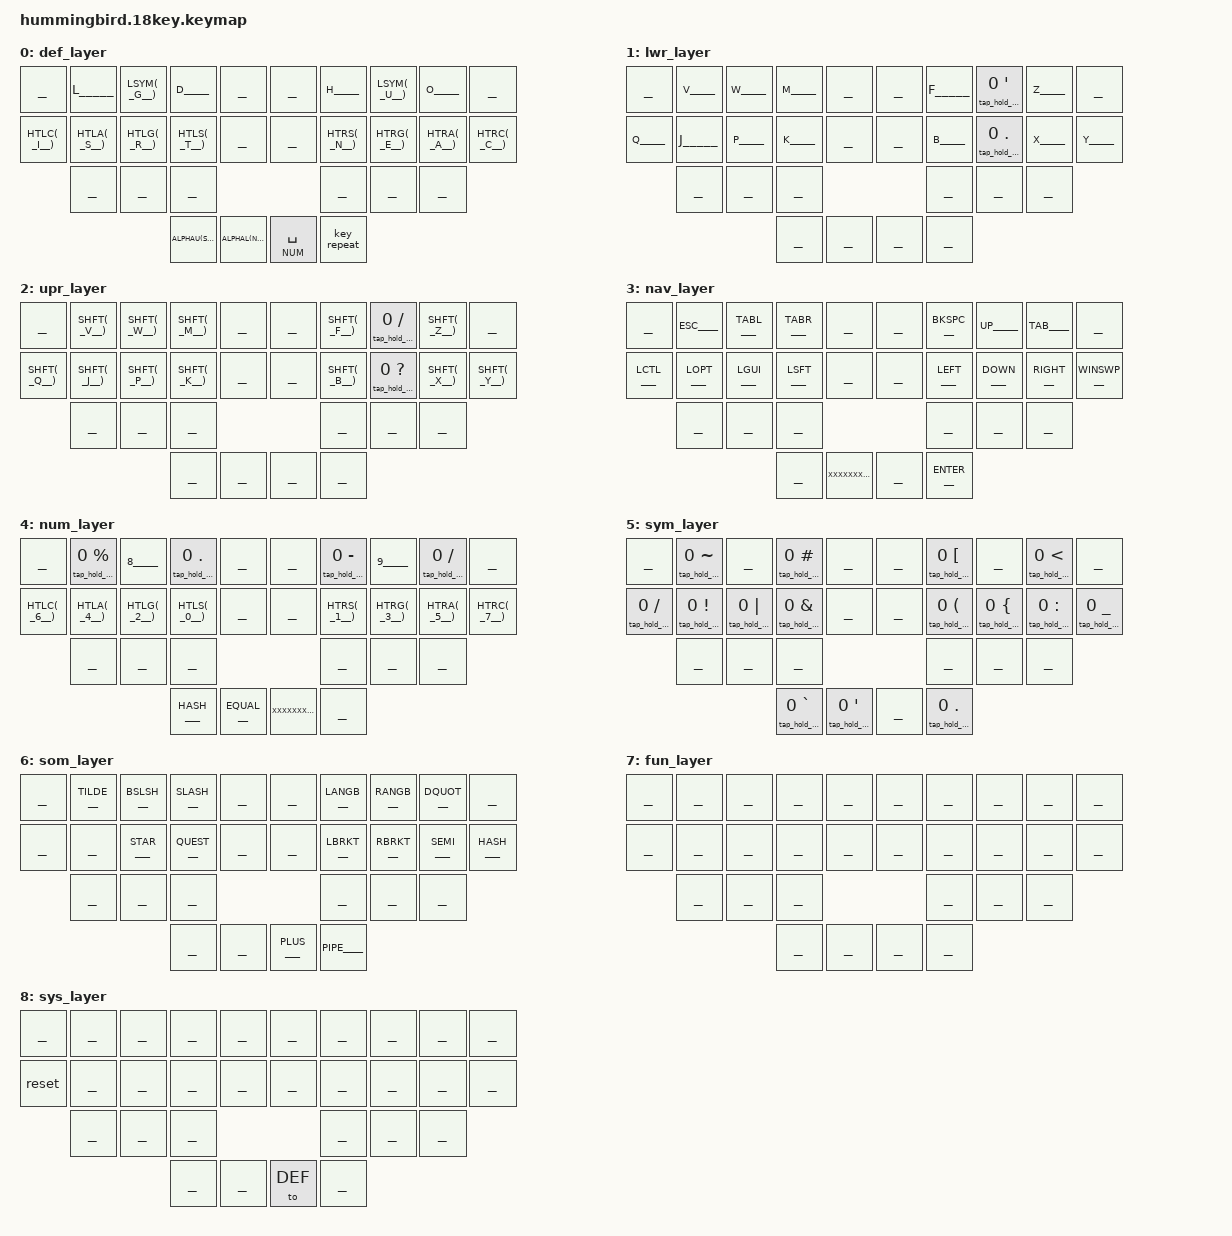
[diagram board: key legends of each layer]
#define HOST_OS 2

#include <behaviors.dtsi>
#include <dt-bindings/zmk/keys.h>
#include <dt-bindings/zmk/bt.h>

#include "./hummingbird.helpers.h"
#include "./nodefree/helpers.h"
#include "./nodefree/keypos_30key.h"
#include "./keycodes.h"

/**
 * ----------------------------------------------
 * DEFAULT ALPHA LAYER
 * ----------------------------------------------
 */ 
ZMK_COMBO(caps_word, &caps_word,  LM1 RM1, DEF, 80)
ZMK_COMBO(esc,       &kp ESC,   LT2 LT1, DEF, 40)

#define LSYM(KEY) HL(SYM, KEY) 


ZMK_LAYER(def_layer,
// ╭─────────────┬─────────────┬─────────────┬─────────────┬─────────────╮   ╭─────────────┬─────────────┬─────────────┬─────────────┬─────────────╮
     ___________   _____L_____   LSYM(__G__)   _____D_____   ___________       ___________   _____H_____   LSYM(__U__)   _____O_____   ___________ 
// ├─────────────┼─────────────┼─────────────┼─────────────┼─────────────┤   ├─────────────┼─────────────┼─────────────┼─────────────┼─────────────┤
     HTLC(__I__)   HTLA(__S__)   HTLG(__R__)   HTLS(__T__)   ___________       ___________   HTRS(__N__)   HTRG(__E__)   HTRA(__A__)   HTRC(__C__) 
// ├─────────────┼─────────────┼─────────────┼─────────────┼─────────────┤   ╰─────────────┼─────────────┼─────────────┼─────────────┼─────────────╯
                   ___________   ___________   ___________                                   ___________   ___________   ___________ 
//               ╰─────────────┼─────────────┼─────────────╯                               ╰─────────────┴─────────────┴─────────────╯
                                               ALPHAU(SYM)   ALPHAL(NAV)       &lt NUM SPC   &key_repeat
//                                           ╰─────────────┴─────────────╯   ╰─────────────┴─────────────╯
)


/**
 * ----------------------------------------------
 * LOWER ALPHA LAYER
 * ----------------------------------------------
 */ 
TAP_HOLD_MACRO(QUOTE, DOUBLE_QUOTES)
#define ___QUOTE___ &tap_hold_QUOTE 0 SINGLE_QUOTE

TAP_HOLD_MACRO(DOTCM, COMMA)
#define ___DOTCM___ &tap_hold_DOTCM 0 DOT

ZMK_UNICODE_SINGLE(da_ae_lwr, N0, N0, E, N6)
ZMK_UNICODE_SINGLE(da_oe_lwr, N0, N0, F, N8)
ZMK_UNICODE_SINGLE(da_aa_lwr, N0, N0, E, N5)

ZMK_COMBO(da_ae_lwr, &da_ae_lwr, RM2 RM1, LWR, 50)
ZMK_COMBO(da_oe_lwr, &da_oe_lwr, RM3 RM2, LWR, 50)
ZMK_COMBO(da_aa_lwr, &da_aa_lwr, RM4 RM3, LWR, 50)

ZMK_LAYER(lwr_layer,
// ╭─────────────┬─────────────┬─────────────┬─────────────┬─────────────╮   ╭─────────────┬─────────────┬─────────────┬─────────────┬─────────────╮
     ___________   _____V_____   _____W_____   _____M_____   ___________       ___________   _____F_____   ___QUOTE___   _____Z_____   ___________ 
// ├─────────────┼─────────────┼─────────────┼─────────────┼─────────────┤   ├─────────────┼─────────────┼─────────────┼─────────────┼─────────────┤
     _____Q_____   _____J_____   _____P_____   _____K_____   ___________       ___________   _____B_____   ___DOTCM___   _____X_____   _____Y_____ 
// ├─────────────┼─────────────┼─────────────┼─────────────┼─────────────┤   ╰─────────────┼─────────────┼─────────────┼─────────────┼─────────────╯
                   ___________   ___________   ___________                                   ___________   ___________   ___________ 
//               ╰─────────────┼─────────────┼─────────────╯                               ╰─────────────┴─────────────┴─────────────╯
                                               ___________   ___________       ___________   ___________
//                                           ╰─────────────┴─────────────╯   ╰─────────────┴─────────────╯
)


/**
 * ----------------------------------------------
 * UPPER ALPHA LAYER
 * ----------------------------------------------
 */ 
#define SHFT(KEY) &kp LS(KEY)

TAP_HOLD_MACRO(QUEX, EXCLAMATION)
#define ___QUEX____ &tap_hold_QUEX 0 QUESTION

TAP_HOLD_MACRO(SLBSL, BACKSLASH)
#define ___SLBSL___ &tap_hold_SLBSL 0 SLASH

ZMK_UNICODE_SINGLE(da_ae_upr, N0, N0, C, N6)
ZMK_UNICODE_SINGLE(da_oe_upr, N0, N0, D, N8)
ZMK_UNICODE_SINGLE(da_aa_upr, N0, N0, C, N5)

ZMK_COMBO(da_ae_upr, &da_ae_upr, RM2 RM1, UPR, 50)
ZMK_COMBO(da_oe_upr, &da_oe_upr, RM3 RM2, UPR, 50)
ZMK_COMBO(da_aa_upr, &da_aa_upr, RM4 RM3, UPR, 50)

ZMK_LAYER(upr_layer,
// ╭─────────────┬─────────────┬─────────────┬─────────────┬─────────────╮   ╭─────────────┬─────────────┬─────────────┬─────────────┬─────────────╮
     ___________   SHFT(__V__)   SHFT(__W__)   SHFT(__M__)   ___________       ___________   SHFT(__F__)   ___SLBSL___   SHFT(__Z__)   ___________ 
// ├─────────────┼─────────────┼─────────────┼─────────────┼─────────────┤   ├─────────────┼─────────────┼─────────────┼─────────────┼─────────────┤
     SHFT(__Q__)   SHFT(__J__)   SHFT(__P__)   SHFT(__K__)   ___________       ___________   SHFT(__B__)   ___QUEX____   SHFT(__X__)   SHFT(__Y__) 
// ├─────────────┼─────────────┼─────────────┼─────────────┼─────────────┤   ╰─────────────┼─────────────┼─────────────┼─────────────┼─────────────╯
                   ___________   ___________   ___________                                   ___________   ___________   ___________ 
//               ╰─────────────┼─────────────┼─────────────╯                               ╰─────────────┴─────────────┴─────────────╯
                                               ___________   ___________       ___________   ___________
//                                           ╰─────────────┴─────────────╯   ╰─────────────┴─────────────╯
)


/**
 * ----------------------------------------------
 * NAV LAYER
 * ----------------------------------------------
 */ 
ZMK_COMBO(copy,      &kp LG(C), LM3 LM2, NAV, 20)
ZMK_COMBO(cut,       &kp LG(X), LM3 LM1, NAV, 20)
ZMK_COMBO(paste,     &kp LG(V), LM2 LM1, NAV, 20)
ZMK_COMBO(tab,       &kp TAB,   RM2 RM1, NAV, 40)

ZMK_LAYER(nav_layer,
// ╭─────────────┬─────────────┬─────────────┬─────────────┬─────────────╮   ╭─────────────┬─────────────┬─────────────┬─────────────┬─────────────╮
     ___________   ____ESC____   ___TABL____   ___TABR____   ___________       ___________   ___BKSPC___   ____UP_____   ____TAB____   ___________ 
// ├─────────────┼─────────────┼─────────────┼─────────────┼─────────────┤   ├─────────────┼─────────────┼─────────────┼─────────────┼─────────────┤
     ___LCTL____   ___LOPT____   ___LGUI____   ___LSFT____   ___________       ___________   ___LEFT____   ___DOWN____   ___RIGHT___   __WINSWP___ 
// ├─────────────┼─────────────┼─────────────┼─────────────┼─────────────┤   ╰─────────────┼─────────────┼─────────────┼─────────────┼─────────────╯
                   ___________   ___________   ___________                                   ___________   ___________   ___________ 
//               ╰─────────────┼─────────────┼─────────────╯                               ╰─────────────┴─────────────┴─────────────╯
                                               ___________   XXXXXXXXXXX       ___________   ___ENTER___
//                                           ╰─────────────┴─────────────╯   ╰─────────────┴─────────────╯
)

/**
 * ----------------------------------------------
 * NUM LAYER
 * ----------------------------------------------
 */ 
TAP_HOLD_MACRO(MINPLUS, PLUS)
#define __MINPLUS__ &tap_hold_MINPLUS 0 MINUS 

TAP_HOLD_MACRO(SLASTAR, STAR)
#define __SLASTAR__ &tap_hold_SLASTAR 0 SLASH 

TAP_HOLD_MACRO(PERCAR, CARET)
#define __PERCAR___ &tap_hold_PERCAR 0 PERCENT 

ZMK_LAYER(num_layer,
// ╭─────────────┬─────────────┬─────────────┬─────────────┬─────────────╮   ╭─────────────┬─────────────┬─────────────┬─────────────┬─────────────╮
     ___________   __PERCAR___   _____8_____   ___DOTCM___   ___________       ___________   __MINPLUS__   _____9_____   __SLASTAR__   ___________ 
// ├─────────────┼─────────────┼─────────────┼─────────────┼─────────────┤   ├─────────────┼─────────────┼─────────────┼─────────────┼─────────────┤
     HTLC(__6__)   HTLA(__4__)   HTLG(__2__)   HTLS(__0__)   ___________       ___________   HTRS(__1__)   HTRG(__3__)   HTRA(__5__)   HTRC(__7__)
// ├─────────────┼─────────────┼─────────────┼─────────────┼─────────────┤   ╰─────────────┼─────────────┼─────────────┼─────────────┼─────────────╯
                   ___________   ___________   ___________                                   ___________   ___________   ___________ 
//               ╰─────────────┼─────────────┼─────────────╯                               ╰─────────────┴─────────────┴─────────────╯
                                               ___HASH____   ___EQUAL___       XXXXXXXXXXX   ___________
//                                           ╰─────────────┴─────────────╯   ╰─────────────┴─────────────╯
)


/**
 * ----------------------------------------------
 * SYM LAYER
 * ----------------------------------------------
 */ 
TAP_HOLD_MACRO(PARN, RIGHT_PARENTHESIS)
#define ___PARN____ &tap_hold_PARN 0 LEFT_PARENTHESIS

TAP_HOLD_MACRO(BRAC, RIGHT_BRACE)
#define ___BRAC____ &tap_hold_BRAC 0 LEFT_BRACE

TAP_HOLD_MACRO(BRKT, RIGHT_BRACKET)
#define ___BRKT____ &tap_hold_BRKT 0 LEFT_BRACKET

TAP_HOLD_MACRO(ANGB, GREATER_THAN)
#define ___ANGB____ &tap_hold_ANGB 0 LESS_THAN

TAP_HOLD_MACRO(TILCAR_, CARET)
#define __TILCAR___ &tap_hold_TILCAR_ 0 TILDE

TAP_HOLD_MACRO(HASHAT, AT_SIGN)
#define __HASHAT___ &tap_hold_HASHAT 0 HASH

TAP_HOLD_MACRO(BANGSTR, STAR)
#define __BANGSTR__ &tap_hold_BANGSTR 0 EXCLAMATION

TAP_HOLD_MACRO(PIPER, PERCENT)
#define ___PIPER___ &tap_hold_PIPER 0 PIPE

TAP_HOLD_MACRO(AMPEQ, EQUAL)
#define ___AMPEQ___ &tap_hold_AMPEQ 0 AMPERSAND

TAP_HOLD_MACRO(GRVDLR, DOLLAR)
#define __GRVDLR___ &tap_hold_GRVDLR 0 GRAVE

TAP_HOLD_MACRO(DOTHUH, QUESTION)
#define __DOTHUH___ &tap_hold_DOTHUH 0 DOT

TAP_HOLD_MACRO(COLSEMI, SEMICOLON)
#define __COLSEMI__ &tap_hold_COLSEMI 0 COLON

TAP_HOLD_MACRO(UNDRMIN, MINUS)
#define __UNDRMIN__ &tap_hold_UNDRMIN 0 UNDERSCORE

ZMK_LAYER(sym_layer,
// ╭─────────────┬─────────────┬─────────────┬─────────────┬─────────────╮   ╭─────────────┬─────────────┬─────────────┬─────────────┬─────────────╮
     ___________   __TILCAR___   ___________   __HASHAT___   ___________       ___________   ___BRKT____   ___________   ___ANGB____   ___________ 
// ├─────────────┼─────────────┼─────────────┼─────────────┼─────────────┤   ├─────────────┼─────────────┼─────────────┼─────────────┼─────────────┤
     ___SLBSL___   __BANGSTR__   ___PIPER___   ___AMPEQ___   ___________       ___________   ___PARN____   ___BRAC____   __COLSEMI__   __UNDRMIN__ 
// ├─────────────┼─────────────┼─────────────┼─────────────┼─────────────┤   ╰─────────────┼─────────────┼─────────────┼─────────────┼─────────────╯
                   ___________   ___________   ___________                                   ___________   ___________   ___________ 
//               ╰─────────────┼─────────────┼─────────────╯                               ╰─────────────┴─────────────┴─────────────╯
                                               __GRVDLR___   ___QUOTE___       ___________   __DOTHUH___
//                                           ╰─────────────┴─────────────╯   ╰─────────────┴─────────────╯
)

ZMK_LAYER(som_layer,
// ╭─────────────┬─────────────┬─────────────┬─────────────┬─────────────╮   ╭─────────────┬─────────────┬─────────────┬─────────────┬─────────────╮
     ___________   ___TILDE___   ___BSLSH___   ___SLASH___   ___________       ___________   ___LANGB___   ___RANGB___   ___DQUOT___   ___________ 
// ├─────────────┼─────────────┼─────────────┼─────────────┼─────────────┤   ├─────────────┼─────────────┼─────────────┼─────────────┼─────────────┤
     ___________   ___________   ___STAR____   ___QUEST___   ___________       ___________   ___LBRKT___   ___RBRKT___   ___SEMI____   ___HASH____ 
// ├─────────────┼─────────────┼─────────────┼─────────────┼─────────────┤   ╰─────────────┼─────────────┼─────────────┼─────────────┼─────────────╯
                   ___________   ___________   ___________                                   ___________   ___________   ___________ 
//               ╰─────────────┼─────────────┼─────────────╯                               ╰─────────────┴─────────────┴─────────────╯
                                               ___________   ___________       ___PLUS____   ___PIPE____
//                                           ╰─────────────┴─────────────╯   ╰─────────────┴─────────────╯
)

ZMK_LAYER(fun_layer,
// ╭─────────────┬─────────────┬─────────────┬─────────────┬─────────────╮   ╭─────────────┬─────────────┬─────────────┬─────────────┬─────────────╮
     ___________   ___________   ___________   ___________   ___________       ___________   ___________   ___________   ___________   ___________ 
// ├─────────────┼─────────────┼─────────────┼─────────────┼─────────────┤   ├─────────────┼─────────────┼─────────────┼─────────────┼─────────────┤
     ___________   ___________   ___________   ___________   ___________       ___________   ___________   ___________   ___________   ___________ 
// ├─────────────┼─────────────┼─────────────┼─────────────┼─────────────┤   ╰─────────────┼─────────────┼─────────────┼─────────────┼─────────────╯
                   ___________   ___________   ___________                                   ___________   ___________   ___________ 
//               ╰─────────────┼─────────────┼─────────────╯                               ╰─────────────┴─────────────┴─────────────╯
                                               ___________   ___________       ___________   ___________
//                                           ╰─────────────┴─────────────╯   ╰─────────────┴─────────────╯
)

ZMK_LAYER(sys_layer,
// ╭─────────────┬─────────────┬─────────────┬─────────────┬─────────────╮   ╭─────────────┬─────────────┬─────────────┬─────────────┬─────────────╮
     ___________   ___________   ___________   ___________   ___________       ___________   ___________   ___________   ___________   ___________ 
// ├─────────────┼─────────────┼─────────────┼─────────────┼─────────────┤   ├─────────────┼─────────────┼─────────────┼─────────────┼─────────────┤
     &reset        ___________   ___________   ___________   ___________       ___________   ___________   ___________   ___________   ___________ 
// ├─────────────┼─────────────┼─────────────┼─────────────┼─────────────┤   ╰─────────────┼─────────────┼─────────────┼─────────────┼─────────────╯
                   ___________   ___________   ___________                                   ___________   ___________   ___________ 
//               ╰─────────────┼─────────────┼─────────────╯                               ╰─────────────┴─────────────┴─────────────╯
                                               ___________   ___________       &to DEF       ___________
//                                           ╰─────────────┴─────────────╯   ╰─────────────┴─────────────╯
)

/*                KEY POSITIONS

  ╭────────────────────╮ ╭────────────────────╮
  │  0   1   2   3   4 │ │  5   6   7   8   9 │
  │ 10  11  12  13  14 │ │ 15  16  17  18  19 │ 
  │     20  21  22     │ │     23  24 25      │
  ╰───────────╮ 26  27 │ │ 28  29 ╭───────────╯
              ╰────────╯ ╰────────╯
*/

// ZMK_COMBO(to_sys, &to SYS, 11 12, SYM)



/**
 * TEMPLATES
 
// ╭─────────────┬─────────────┬─────────────┬─────────────┬─────────────╮   ╭─────────────┬─────────────┬─────────────┬─────────────┬─────────────╮
     ___________   ___________   ___________   ___________   ___________       ___________   ___________   ___________   ___________   ___________ 
// ├─────────────┼─────────────┼─────────────┼─────────────┼─────────────┤   ├─────────────┼─────────────┼─────────────┼─────────────┼─────────────┤
     ___________   ___________   ___________   ___________   ___________       ___________   ___________   ___________   ___________   ___________ 
// ├─────────────┼─────────────┼─────────────┼─────────────┼─────────────┤   ╰─────────────┼─────────────┼─────────────┼─────────────┼─────────────╯
                   ___________   ___________   ___________                                   ___________   ___________   ___________ 
//               ╰─────────────┼─────────────┼─────────────╯                               ╰─────────────┴─────────────┴─────────────╯
                                               ___________   ___________       ___________   ___________
//                                           ╰─────────────┴─────────────╯   ╰─────────────┴─────────────╯

// ╭─────────────┬─────────────┬─────────────┬─────────────┬─────────────╮   ╭─────────────┬─────────────┬─────────────┬─────────────┬─────────────╮
     XXXXXXXXXXX   XXXXXXXXXXX   XXXXXXXXXXX   XXXXXXXXXXX       XXXXXXXXXXX   XXXXXXXXXXX   XXXXXXXXXXX   XXXXXXXXXXX   XXXXXXXXXXX 
// ├─────────────┼─────────────┼─────────────┼─────────────┼─────────────┤   ├─────────────┼─────────────┼─────────────┼─────────────┼─────────────┤
     XXXXXXXXXXX   XXXXXXXXXXX   XXXXXXXXXXX   XXXXXXXXXXX   XXXXXXXXXXX       XXXXXXXXXXX   XXXXXXXXXXX   XXXXXXXXXXX   XXXXXXXXXXX   XXXXXXXXXXX 
// ├─────────────┼─────────────┼─────────────┼─────────────┼─────────────┤   ╰─────────────┼─────────────┼─────────────┼─────────────┼─────────────╯
                   XXXXXXXXXXX   XXXXXXXXXXX   XXXXXXXXXXX                                   XXXXXXXXXXX   XXXXXXXXXXX   XXXXXXXXXXX 
//               ╰─────────────┼─────────────┼─────────────╯                               ╰─────────────┴─────────────┴─────────────╯
                                               XXXXXXXXXXX   XXXXXXXXXXX       XXXXXXXXXXX   XXXXXXXXXXX
//                                           ╰─────────────┴─────────────╯   ╰─────────────┴─────────────╯
*/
